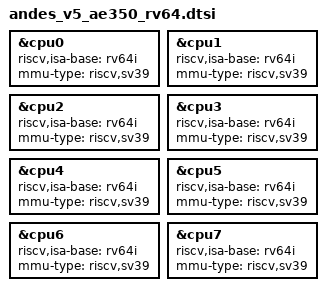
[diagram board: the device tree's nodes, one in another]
/*
 * Copyright (c) 2026 Andes Technology Corporation
 *
 * SPDX-License-Identifier: Apache-2.0
 */

#include <riscv/andes/andes_v5_ae350.dtsi>

&cpu0 {
	riscv,isa-base = "rv64i";
	mmu-type = "riscv,sv39";
};

&cpu1 {
	riscv,isa-base = "rv64i";
	mmu-type = "riscv,sv39";
};

&cpu2 {
	riscv,isa-base = "rv64i";
	mmu-type = "riscv,sv39";
};

&cpu3 {
	riscv,isa-base = "rv64i";
	mmu-type = "riscv,sv39";
};

&cpu4 {
	riscv,isa-base = "rv64i";
	mmu-type = "riscv,sv39";
};

&cpu5 {
	riscv,isa-base = "rv64i";
	mmu-type = "riscv,sv39";
};

&cpu6 {
	riscv,isa-base = "rv64i";
	mmu-type = "riscv,sv39";
};

&cpu7 {
	riscv,isa-base = "rv64i";
	mmu-type = "riscv,sv39";
};
